# CRYPTO register map
Vendor: Texas Instruments
Peripheral module from a debugger description file (folder CC26x4).
Registers are 32-bit, write-only, reset 0x0 unless marked. A register's access mark holds for its fields unless they carry their own. Offsets are as the file gives them; lines under a group give offsets from that group; [hi:lo] are bit positions; {n}, {i} and the like mark numbered series; 'fields as' and 'values as' point back to an identical list; <NAME> marks a mode.

## CRYPTO (part 1 of 2) — DMA Crypto Core is a low power low gate count crypto core with DMA capability and local key storage.
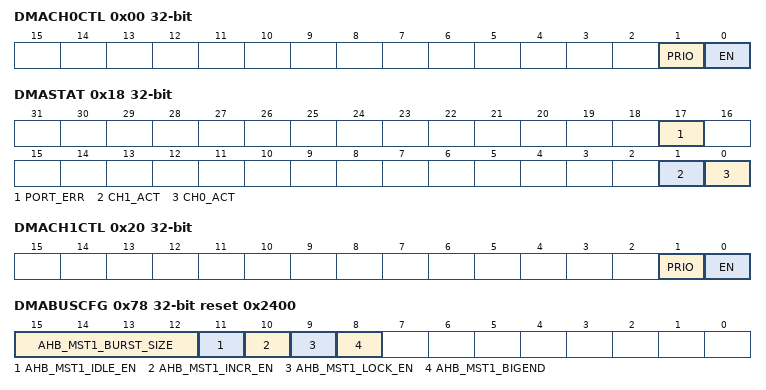
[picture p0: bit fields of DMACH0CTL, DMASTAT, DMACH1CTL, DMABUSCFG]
0x00 DMACH0CTL rw — Channel 0 Control This register is used for channel enabling and priority selection. When a channel is disabled, it becomes inactive only when all ongoing requests are finished.
  [1] PRIO — Channel priority 0: Low 1: High If both channels have the same priority, access of the channels to the external port is arbitrated using the round robin scheme. If one channel has a high priority and another one low, the channel with the high priority is served first, in case of simultaneous access requests.
  [0] EN — Channel enable 0: Disabled 1: Enable Note: Disabling an active channel interrupts the DMA operation. The ongoing block transfer completes, but no new transfers are requested.
0x04 DMACH0EXTADDR rw — Channel 0 External Address
  [31:0] ADDR — Channel external address value When read during operation, it holds the last updated external address after being sent to the master interface. Note: The crypto DMA copies out upto 3 bytes until it hits a word boundary, thus the address need not be word aligned.
0x0C DMACH0LEN rw — Channel 0 DMA Length
  [15:0] DMALEN — Channel DMA length in bytes During configuration, this register contains the DMA transfer length in bytes. During operation, it contains the last updated value of the DMA transfer length after being sent to the master interface. Note: Setting this register to a nonzero value starts the transfer if the channel is enabled. Therefore, this register must be written last when setting up a DMA channel.
0x18 DMASTAT ro — DMAC Status This register provides the actual state of each DMA channel. It also reports port errors in case these were received by the master interface module during the data transfer.
  [17] PORT_ERR — Reflects possible transfer errors on the AHB port.
  [1] CH1_ACT — A value of 1 indicates that channel 1 is active (DMA transfer on-going).
  [0] CH0_ACT — A value of 1 indicates that channel 0 is active (DMA transfer on-going).
0x1C DMASWRESET — DMAC Software Reset Software reset is used to reset the DMAC to stop all transfers and clears the port error status register. After the software reset is performed, all the channels are disabled and no new requests are performed by the channels. The DMAC waits for the existing (active) requests to finish and accordingly sets the DMASTAT.
  [0] SWRES — Software reset enable 0 : Disabled 1 : Enabled (self-cleared to 0) Completion of the software reset must be checked through the DMASTAT
0x20 DMACH1CTL rw — Channel 1 Control This register is used for channel enabling and priority selection. When a channel is disabled, it becomes inactive only when all ongoing requests are finished.
  fields as DMACH0CTL
0x24 DMACH1EXTADDR rw — Channel 1 External Address
  [31:0] ADDR — Channel external address value. When read during operation, it holds the last updated external address after being sent to the master interface. Note: The crypto DMA copies out upto 3 bytes until it hits a word boundary, thus the address need not be word aligned.
0x2C DMACH1LEN rw — Channel 1 DMA Length
  [15:0] DMALEN — Channel DMA length in bytes. During configuration, this register contains the DMA transfer length in bytes. During operation, it contains the last updated value of the DMA transfer length after being sent to the master interface. Note: Setting this register to a nonzero value starts the transfer if the channel is enabled. Therefore, this register must be written last when setting up a DMA channel.
0x78 DMABUSCFG rw reset 0x2400 — DMAC Master Run-time Parameters This register defines all the run-time parameters for the AHB master interface port. These parameters are required for the proper functioning of the EIP-101m AHB master adapter.
  [15:12] AHB_MST1_BURST_SIZE — Maximum burst size that can be performed on the AHB bus
    6=64_BYTE (64 bytes); 5=32_BYTE (32 bytes); 4=16_BYTE (16 bytes); 3=8_BYTE (8 bytes); 2=4_BYTE (4 bytes)
  [11] AHB_MST1_IDLE_EN — Idle insertion between consecutive burst transfers on AHB
    1=IDLE (Idle transfer insertion enabled); 0=NO_IDLE (Do not insert idle transfers.)
  [10] AHB_MST1_INCR_EN — Burst length type of AHB transfer
    1=SPECIFIED (Fixed length bursts or single transfers); 0=UNSPECIFIED (Unspecified length burst transfers)
  [9] AHB_MST1_LOCK_EN — Locked transform on AHB
    1=LOCKED (Transfers are locked); 0=NOT_LOCKED (Transfers are not locked)
  [8] AHB_MST1_BIGEND — Endianess for the AHB master
    1=BIG_ENDIAN; 0=LITTLE_ENDIAN
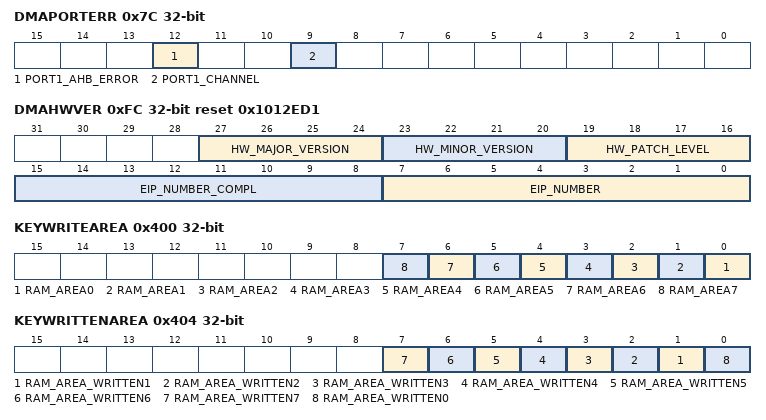
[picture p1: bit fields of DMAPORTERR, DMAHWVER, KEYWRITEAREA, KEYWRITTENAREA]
0x7C DMAPORTERR ro — DMAC Port Error Raw Status This register provides the actual status of individual port errors. It also indicates which channel is serviced by an external AHB port (which is frozen by a port error). A port error aborts operations on all serviced channels (channel enable bit is forced to 0) and prevents further transfers via that port until the error is cleared by writing to the DMASWRESET register.
  [12] PORT1_AHB_ERROR — A value of 1 indicates that the EIP-101 has detected an AHB bus error
  [9] PORT1_CHANNEL — Indicates which channel has serviced last (channel 0 or channel 1) by AHB master port.
0xFC DMAHWVER ro reset 0x1012ED1 — DMAC Version This register contains an indication (or signature) of the EIP type of this DMAC, as well as the hardware version/patch numbers.
  [27:24] HW_MAJOR_VERSION — Major version number
  [23:20] HW_MINOR_VERSION — Minor version number
  [19:16] HW_PATCH_LEVEL — Patch level Starts at 0 at first delivery of this version
  [15:8] EIP_NUMBER_COMPL — Bit-by-bit complement of the EIP_NUMBER field bits.
  [7:0] EIP_NUMBER — Binary encoding of the EIP-number of this DMA controller (209)
0x400 KEYWRITEAREA rw — Key Store Write Area This register defines where the keys should be written in the key store RAM. After writing this register, the key store module is ready to receive the keys through a DMA operation. In case the key data transfer triggered an error in the key store, the error will be available in the interrupt status register after the DMA is finished. The key store write-error is asserted when the programmed/selected area is not completely written. This error is also asserted when the DMA operation writes to ram areas that are not selected. The key store RAM is divided into 8 areas of 128 bits. 192-bit keys written in the key store RAM should start on boundaries of 256 bits. This means that writing a 192-bit key to the key store RAM must be done by writing 256 bits of data with the 64 most-significant bits set to 0. These bits are ignored by the AES engine.
  [all] fields
    1=SEL (This RAM area is selected to be written); 0=NOT_SEL (This RAM area is not selected to be written)
  [n] RAM_AREA{n} (n=0..7) — Each RAM_AREAx represents an area of 128 bits. Select the key store RAM area(s) where the key(s) needs to be written 0: RAM_AREA{n} is not selected to be written. 1: RAM_AREA{n} is selected to be written. Writing to multiple RAM locations is possible only when the selected RAM areas are sequential. Keys that require more than one RAM locations (key size is 192 or 256 bits), must start at one of the following areas: RAM_AREA0, RAM_AREA2, RAM_AREA4, or RAM_AREA6.
0x404 KEYWRITTENAREA rw — Key Store Written Area This register shows which areas of the key store RAM contain valid written keys. When a new key needs to be written to the key store, on a location that is already occupied by a valid key, this key area must be cleared first. This can be done by writing this register before the new key is written to the key store memory. Attempting to write to a key area that already contains a valid key is not allowed and results in an error.
  [n] RAM_AREA_WRITTEN{n} (n=1..7) — On read this bit returns the key area written status. This bit can be reset by writing a 1. Note: This register will be reset on a soft reset initiated by writing to DMASWRESET.SWRES. After a soft reset, all keys must be rewritten to the key store memory.
    1=WRITTEN (This RAM area is written with valid key information); 0=NOT_WRITTEN (This RAM area is not written with valid key information)
  [0] RAM_AREA_WRITTEN0 — On read this bit returns the key area written status. This bit can be reset by writing a 1. Note: This register will be reset on a soft reset initiated by writing to DMASWRESET.SWRES. After a soft reset, all keys must be rewritten to the key store memory.
0x408 KEYSIZE rw reset 0x1 — Key Store Size This register defines the size of the keys that are written with DMA. This register should be configured before writing to the KEY_STORE_WRITE_AREA register.
  [1:0] SIZE — Key size: 00: Reserved When writing this to this register, the KEY_STORE_WRITTEN_AREA register is reset.
    3=256_BIT (256 bits); 2=192_BIT (192 bits); 1=128_BIT (128 bits)
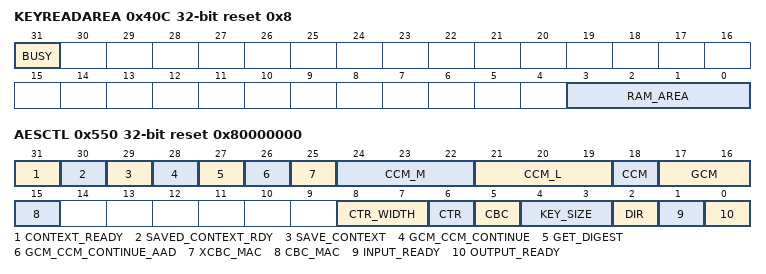
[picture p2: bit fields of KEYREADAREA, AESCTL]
0x40C KEYREADAREA access per field reset 0x8 — Key Store Read Area This register selects the key store RAM area from where the key needs to be read that will be used for an AES operation. The operation directly starts after writing this register. When the operation is finished, the status of the key store read operation is available in the interrupt status register. Key store read error is asserted when a RAM area is selected which does not contain valid written key.
  [31] BUSY ro — Key store operation busy status flag (read only): 0: Operation is complete. 1: Operation is not completed and the key store is busy.
  [3:0] RAM_AREA rw — Selects the area of the key store RAM from where the key needs to be read that will be writen to the AES engine RAM_AREA: RAM areas RAM_AREA0, RAM_AREA2, RAM_AREA4 and RAM_AREA6 are the only valid read areas for 192 and 256 bits key sizes. Only RAM areas that contain valid written keys can be selected.
    8=NO_RAM; {v}=RAM_AREA{v} (v=0..7)
0x500 AESKEY2 — AES_KEY2_0 / AES_GHASH_H_IN_0 Second Key / GHASH Key (internal, but clearable) The following registers are not accessible through the host for reading and writing. They are used to store internally calculated key information and intermediate results. However, when the host performs a write to the any of the respective AES_KEY2_n or AES_KEY3_n addresses, respectively the whole 128-bit AES_KEY2_n or AES_KEY3_n register is cleared to 0s. The AES_GHASH_H_IN_n registers (required for GHASH, which is part of GCM) are mapped to the AES_KEY2_n registers. The (intermediate) authentication result for GCM and CCM is stored in the AES_KEY3_n register.
  [31:0] AES_KEY2 — AES_KEY2/AES_GHASH_H[31:0] For GCM: -[127:0] - GHASH_H - The internally calculated GHASH key is stored in these registers. Only used for modes that use the GHASH function (GCM). -[255:128] - This register is used to store intermediate values and is initialized with 0s when loading a new key. For CCM: -[255:0] - This register is used to store intermediate values. For CBC-MAC: -[255:0] - ZEROES - This register must remain 0.
0x510 AESKEY3 — AES_KEY3_0 / AES_KEY2_4 Third Key / Second Key (internal, but clearable) The following registers are not accessible through the host for reading and writing. They are used to store internally calculated key information and intermediate results. However, when the host performs a write to the any of the respective AES_KEY2_n or AES_KEY3_n addresses, respectively the whole 128-bit AES_KEY2_n or AES_KEY3_n register is cleared to 0s. The AES_GHASH_H_IN_n registers (required for GHASH, which is part of GCM) are mapped to the AES_KEY2_n registers. The (intermediate) authentication result for GCM and CCM is stored in the AES_KEY3_n register.
  [31:0] AES_KEY3 — AES_KEY3[31:0]/AES_KEY2[159:128] For GCM: -[127:0] - GHASH_H - The internally calculated GHASH key is stored in these registers. Only used for modes that use the GHASH function (GCM). -[255:128] - This register is used to store intermediate values and is initialized with 0s when loading a new key. For CCM: -[255:0] - This register is used to store intermediate values. For CBC-MAC: -[255:0] - ZEROES - This register must remain 0.
0x540 AESIV rw — AES initialization vector registers These registers are used to provide and read the IV from the AES engine.
  [31:0] AES_IV — AES_IV[31:0] Initialization vector Used for regular non-ECB modes (CBC/CTR): -[127:0] - AES_IV - For regular AES operations (CBC and CTR) these registers must be written with a new 128-bit IV. After an operation, these registers contain the latest 128-bit result IV, generated by the EIP-120t. If CTR mode is selected, this value is incremented with 0x1: After first use - When a new data block is submitted to the engine For GCM: -[127:0] - AES_IV - For GCM operations, these registers must be written with a new 128-bit IV. After an operation, these registers contain the updated 128-bit result IV, generated by the EIP-120t. Note that bits [127:96] of the IV represent the initial counter value (which is 1 for GCM) and must therefore be initialized to 0x01000000. This value is incremented with 0x1: After first use - When a new data block is submitted to the engine. For CCM: -[127:0] - A0: For CCM this field must be written with value A0, this value is the concatenation of: A0-flags (5-bits of 0 and 3-bits 'L'), Nonce and counter value. 'L' must be a copy from the 'L' value of the AES_CTRL register. This 'L' indicates the width of the Nonce and counter. The loaded counter must be initialized to 0. The total width of A0 is 128-bit. For CBC-MAC: -[127:0] - Zeroes - For CBC-MAC this register must be written with 0s at the start of each operation. After an operation, these registers contain the 128-bit TAG output, generated by the EIP-120t.
0x550 AESCTL access per field reset 0x80000000 — AES Control AES input/output buffer control and mode register This register specifies the AES mode of operation for the EIP-120t. Electronic codebook (ECB) mode is automatically selected if bits [28:5] of this register are all 0.
  [31] CONTEXT_READY ro — If 1, this read-only status bit indicates that the context data registers can be overwritten and the host is permitted to write the next context.
  [30] SAVED_CONTEXT_RDY rw — If 1, this status bit indicates that an AES authentication TAG and/or IV block(s) is/are available for the host to retrieve. This bit is only asserted if the save_context bit is set to 1. The bit is mutual exclusive with the context_ready bit. Writing one clears the bit to 0, indicating the AES core can start its next operation. This bit is also cleared when the 4th word of the output TAG and/or IV is read. Note: All other mode bit writes are ignored when this mode bit is written with 1. Note: This bit is controlled automatically by the EIP-120t for TAG read DMA operations.
  [29] SAVE_CONTEXT rw — This bit indicates that an authentication TAG or result IV needs to be stored as a result context. Typically this bit must be set for authentication modes returning a TAG (CBC-MAC, GCM and CCM), or for basic encryption modes that require future continuation with the current result IV. If this bit is set, the engine retains its full context until the TAG and/or IV registers are read. The TAG or IV must be read before the AES engine can start a new operation.
  [28] GCM_CCM_CONTINUE rw — Continue processing of an interrupted AES-GCM or AES-CCM operation in the crypto/payload phase. Set this write-only signal to ‘1b’ together with the regular mode bit settings for a GCM or CCM operation, to continue processing from the next full block (128 bits) boundary. Before setting this bit all applicable context to resume processing must have been loaded into the engine: Keys, IV, intermediate digest/TAG and block counter. The mode can be written together with this bit, as it is part of the same register.
  [27] GET_DIGEST rw — Interrupt processing and generate an intermediate digest during an AES-GCM or AES-CCM operation. Set this write-only signal to ‘1b’ to interrupt GCM or CCM processing at the next full block (128 bits) boundary. An intermediate digest may be requested during the encryption/decryption data phase or in the AAD phase. Interruption can only be done on full block (128 bits) boundaries.
  [26] GCM_CCM_CONTINUE_AAD rw — Continue processing of an interrupted AES-GCM or AES-CCM operation in the AAD phase. Set this write-only signal to ‘1b’ together with the regular mode bit settings for a GCM or CCM operation, to continue processing from the next full AAD block (128 bits) boundary. Before setting this bit all applicable context to resume processing must have been loaded into the engine: Keys, IV, intermediate digest/TAG, block counter and the CCM align data word (the latter is for CCM mode only). The mode can be written together with this bit, as it is part of the same register.
  [25] XCBC_MAC rw — Set to ‘1’ to select AES-XCBC MAC mode. The direction bit must be set to ‘1’ for this mode. Selecting this mode requires writing the length register
  [24:22] CCM_M rw — Defines M, which indicates the length of the authentication field for CCM operations; the authentication field length equals two times (the value of CCM-M plus one). Note: The EIP-120t always returns a 128-bit authentication field, of which the M least significant bytes are valid. All values are supported.
  [21:19] CCM_L rw — Defines L, which indicates the width of the length field for CCM operations; the length field in bytes equals the value of CMM-L plus one. All values are supported.
  [18] CCM rw — If set to 1, AES-CCM is selected AES-CCM is a combined mode, using AES for authentication and encryption. Note: Selecting AES-CCM mode requires writing of the AAD length register after all other registers. Note: The CTR mode bit in this register must also be set to 1 to enable AES-CTR; selecting other AES modes than CTR mode is invalid.
  [17:16] GCM rw — Set these bits to 11 to select AES-GCM mode. AES-GCM is a combined mode, using the Galois field multiplier GF(2 to the power of 128) for authentication and AES-CTR mode for encryption. Note: The CTR mode bit in this register must also be set to 1 to enable AES-CTR Bit combination description: 00 = No GCM mode 01 = Reserved, do not select 10 = Reserved, do not select 11 = Autonomous GHASH (both H- and Y0-encrypted calculated internally) Note: The EIP-120t-1 configuration only supports mode 11 (autonomous GHASH), other GCM modes are not allowed.
  [15] CBC_MAC rw — Set to 1 to select AES-CBC MAC mode. The direction bit must be set to 1 for this mode. Selecting this mode requires writing the length register after all other registers.
  [8:7] CTR_WIDTH rw — Specifies the counter width for AES-CTR mode 00 = 32-bit counter 01 = 64-bit counter 10 = 96-bit counter 11 = 128-bit counter
    3=128_BIT (128 bits); 2=96_BIT (96 bits); 1=64_BIT (64 bits); 0=32_BIT (32 bits)
  [6] CTR rw — If set to 1, AES counter mode (CTR) is selected. Note: This bit must also be set for GCM and CCM, when encryption/decryption is required.
  [5] CBC rw — If set to 1, cipher-block-chaining (CBC) mode is selected.
  [4:3] KEY_SIZE ro — This read-only field specifies the key size. The key size is automatically configured when a new key is loaded through the key store module. 00 = N/A - Reserved 01 = 128-bit 10 = 192-bit 11 = 256-bit
  [2] DIR rw — If set to 1 an encrypt operation is performed. If set to 0 a decrypt operation is performed. This bit must be written with a 1 when CBC-MAC is selected.
  [1] INPUT_READY rw — If 1, this status bit indicates that the 16-byte AES input buffer is empty. The host is permitted to write the next block of data. Writing 0 clears the bit to 0 and indicates that the AES core can use the provided input data block. Writing 1 to this bit is ignored. Note: For DMA operations, this bit is automatically controlled by the EIP-120t. After reset, this bit is 0. After writing a context, this bit becomes 1.
  [0] OUTPUT_READY rw — If 1, this status bit indicates that an AES output block is available to be retrieved by the host. Writing 0 clears the bit to 0 and indicates that output data is read by the host. The AES core can provide a next output data block. Writing 1 to this bit is ignored. Note: For DMA operations, this bit is automatically controlled by the EIP-120t.
0x554 AESDATALEN0 — AES Crypto Length 0 (LSW) These registers are used to write the Length values to the EIP-120t. While processing, the length values decrement to 0. If both lengths are 0, the data stream is finished and a new context is requested. For basic AES modes (ECB, CBC, and CTR), a crypto length of 0 can be written if multiple streams need to be processed with the same key. Writing 0 length results in continued data requests until a new context is written. For the other modes (CBC-MAC, GCM, and CCM) no (new) data requests are done if the length decrements to or equals 0. It is advised to write a new length per packet. If the length registers decrement to 0, no new data is processed until a new context or length value is written. When writing a new mode without writing the length registers, the length register values from the previous context is reused.
  [31:0] C_LENGTH — C_LENGTH[31:0] Bits [60:0] of the crypto length registers (LSW and MSW) store the cryptographic data length in bytes for all modes. Once processing with this context is started, this length decrements to 0. Data lengths up to (261: 1) bytes are allowed. For GCM, any value up to 236 - 32 bytes can be used. This is because a 32-bit counter mode is used; the maximum number of 128-bit blocks is 232 - 2, resulting in a maximum number of bytes of 236 - 32. A write to this register triggers the engine to start using this context. This is valid for all modes except GCM and CCM. Note: For the combined modes (GCM and CCM), this length does not include the authentication only data; the authentication length is specified in the AESAUTHLEN register All modes must have a length greater than 0. For the combined modes, it is allowed to have one of the lengths equal to 0. For the basic encryption modes (ECB, CBC, and CTR) it is allowed to program zero to the length field; in that case the length is assumed infinite. All data must be byte (8-bit) aligned for stream cipher modes; bit aligned data streams are not supported by the EIP-120t. For block cipher modes, the data length must be programmed in multiples of the block cipher size, 16 bytes. For a host read operation, these registers return all-0s.
0x558 AESDATALEN1 — AES Crypto Length 1 (MSW) These registers are used to write the Length values to the EIP-120t. While processing, the length values decrement to 0. If both lengths are 0, the data stream is finished and a new context is requested. For basic AES modes (ECB, CBC, and CTR), a crypto length of 0 can be written if multiple streams need to be processed with the same key. Writing 0 length results in continued data requests until a new context is written. For the other modes (CBC-MAC, GCM and CCM) no (new) data requests are done if the length decrements to or equals 0. It is advised to write a new length per packet. If the length registers decrement to 0, no new data is processed until a new context or length value is written. When writing a new mode without writing the length registers, the length register values from the previous context is reused.
  [28:0] C_LENGTH — C_LENGTH[60:32] Bits [60:0] of the crypto length registers (LSW and MSW) store the cryptographic data length in bytes for all modes. Once processing with this context is started, this length decrements to 0. Data lengths up to (261: 1) bytes are allowed. For GCM, any value up to 236 - 32 bytes can be used. This is because a 32-bit counter mode is used; the maximum number of 128-bit blocks is 232 - 2, resulting in a maximum number of bytes of 236 - 32. A write to this register triggers the engine to start using this context. This is valid for all modes except GCM and CCM. Note: For the combined modes (GCM and CCM), this length does not include the authentication only data; the authentication length is specified in the AESAUTHLEN register All modes must have a length greater than 0. For the combined modes, it is allowed to have one of the lengths equal to 0. For the basic encryption modes (ECB, CBC, and CTR) it is allowed to program zero to the length field; in that case the length is assumed infinite. All data must be byte (8-bit) aligned for stream cipher modes; bit aligned data streams are not supported by the EIP-120t. For block cipher modes, the data length must be programmed in multiples of the block cipher size, 16 bytes. For a host read operation, these registers return all-0s.
0x55C AESAUTHLEN — AES Authentication Length
  [31:0] AUTH_LENGTH — Bits [31:0] of the authentication length register store the authentication data length in bytes for combined modes only (GCM or CCM). Supported AAD-lengths for CCM are from 0 to (2^16 - 2^8) bytes. For GCM any value up to (2^32 - 1) bytes can be used. Once processing with this context is started, this length decrements to 0. A write to this register triggers the engine to start using this context for GCM and CCM. For a host read operation, these registers return all-0s.
{0x560+4i} AESDATAOUT{i} ro (i=0..3) — Data Input/Output
  [31:0] DATA — Data register 0 for output block data from the Crypto peripheral. These bits = AES Output Data[31:0] of {127:0] For normal operations, this register is not used, since data input and output is transferred from and to the AES engine via DMA. For a Host read operation, these registers contain the 128-bit output block from the latest AES operation. Reading from a word-aligned offset within this address range will read one word (4 bytes) of data out the 4-word deep (16 bytes = 128-bits AES block) data output buffer. The words (4 words, one full block) should be read before the core will move the next block to the data output buffer. To empty the data output buffer, AESCTL.OUTPUT_READY must be written. For the modes with authentication (CBC-MAC, GCM and CCM), the invalid (message) bytes/words can be written with any data. Note: The AAD / authentication only data is not copied to the output buffer but only used for authentication.
0x560 AESDATAIN0 — AES Data Input_Output 0 The data registers are typically accessed through the DMA and not with host writes and/or reads. However, for debugging purposes the data input/output registers can be accessed via host write and read operations. The registers are used to buffer the input/output data blocks to/from the EIP-120t. Note: The data input buffer (AES_DATA_IN_n) and data output buffer (AES_DATA_OUT_n) are mapped to the same address locations. Writes (both DMA and host) to these addresses load the Input Buffer while reads pull from the Output Buffer. Therefore, for write access, the data input buffer is written; for read access, the data output buffer is read. The data input buffer must be written before starting an operation. The data output buffer contains valid data on completion of an operation. Therefore, any 128-bit data block can be split over multiple 32-bit word transfers; these can be mixed with other host transfers over the external interface.
  [31:0] AES_DATA_IN_OUT — AES input data[31:0] / AES output data[31:0] Data registers for input/output block data to/from the EIP-120t. For normal operations, this register is not used, since data input and output is transferred from and to the AES core via DMA. For a host write operation, these registers must be written with the 128-bit input block for the next AES operation. Writing at a word-aligned offset within this address range stores the word (4 bytes) of data into the corresponding position of 4-word deep (16 bytes = 128-bit AES block) data input buffer. This buffer is used for the next AES operation. If the last data block is not completely filled with valid data (see notes below), it is allowed to write only the words with valid data. Next AES operation is triggered by writing to the input_ready flag of the AES_CTRL register. For a host read operation, these registers contain the 128-bit output block from the latest AES operation. Reading from a word-aligned offset within this address range reads one word (4 bytes) of data out the 4-word deep (16 bytes = 128-bits AES block) data output buffer. The words (4 words, one full block) should be read before the core will move the next block to the data output buffer. To empty the data output buffer, the output_ready flag of the AES_CTRL register must be written. For the modes with authentication (CBC-MAC, GCM and CCM), the invalid (message) bytes/words can be written with any data. Note: AES typically operates on 128 bits block multiple input data. The CTR, GCM and CCM modes form an exception. The last block of a CTR-mode message may contain less than 128 bits (refer to [NIST 800-38A]). For GCM/CCM, the last block of both AAD and message data may contain less than 128 bits (refer to [NIST 800-38D]). The EIP-120t automatically pads or masks misaligned ending data blocks with 0s for GCM, CCM and CBC-MAC. For CTR mode, the remaining data in an unaligned data block is ignored. Note: The AAD / authentication only data is not copied to the output buffer but only used for authentication.
0x564 AESDATAIN1 — AES Data Input_Output 0 The data registers are typically accessed through the DMA and not with host writes and/or reads. However, for debugging purposes the data input/output registers can be accessed via host write and read operations. The registers are used to buffer the input/output data blocks to/from the EIP-120t. Note: The data input buffer (AES_DATA_IN_n) and data output buffer (AES_DATA_OUT_n) are mapped to the same address locations. Writes (both DMA and host) to these addresses load the Input Buffer while reads pull from the Output Buffer. Therefore, for write access, the data input buffer is written; for read access, the data output buffer is read. The data input buffer must be written before starting an operation. The data output buffer contains valid data on completion of an operation. Therefore, any 128-bit data block can be split over multiple 32-bit word transfers; these can be mixed with other host transfers over the external interface.
  [31:0] AES_DATA_IN_OUT — AES input data[31:0] / AES output data[63:32] Data registers for input/output block data to/from the EIP-120t. For normal operations, this register is not used, since data input and output is transferred from and to the AES core via DMA. For a host write operation, these registers must be written with the 128-bit input block for the next AES operation. Writing at a word-aligned offset within this address range stores the word (4 bytes) of data into the corresponding position of 4-word deep (16 bytes = 128-bit AES block) data input buffer. This buffer is used for the next AES operation. If the last data block is not completely filled with valid data (see notes below), it is allowed to write only the words with valid data. Next AES operation is triggered by writing to the input_ready flag of the AES_CTRL register. For a host read operation, these registers contain the 128-bit output block from the latest AES operation. Reading from a word-aligned offset within this address range reads one word (4 bytes) of data out the 4-word deep (16 bytes = 128-bits AES block) data output buffer. The words (4 words, one full block) should be read before the core will move the next block to the data output buffer. To empty the data output buffer, the output_ready flag of the AES_CTRL register must be written. For the modes with authentication (CBC-MAC, GCM and CCM), the invalid (message) bytes/words can be written with any data. Note: AES typically operates on 128 bits block multiple input data. The CTR, GCM and CCM modes form an exception. The last block of a CTR-mode message may contain less than 128 bits (refer to [NIST 800-38A]). For GCM/CCM, the last block of both AAD and message data may contain less than 128 bits (refer to [NIST 800-38D]). The EIP-120t automatically pads or masks misaligned ending data blocks with 0s for GCM, CCM and CBC-MAC. For CTR mode, the remaining data in an unaligned data block is ignored. Note: The AAD / authentication only data is not copied to the output buffer but only used for authentication.
0x568 AESDATAIN2 — AES Data Input_Output 2 The data registers are typically accessed via DMA and not with host writes and/or reads. However, for debugging purposes the Data Input/Output Registers can be accessed via host write and read operations. The registers are used to buffer the input/output data blocks to/from the EIP-120t. Note: The data input buffer (AES_DATA_IN_n) and data output buffer (AES_DATA_OUT_n) are mapped to the same address locations. Writes (both DMA and host) to these addresses load the Input Buffer while reads pull from the Output Buffer. Therefore, for write access, the data input buffer is written; for read access, the data output buffer is read. The data input buffer must be written before starting an operation. The data output buffer contains valid data on completion of an operation. Therefore, any 128-bit data block can be split over multiple 32-bit word transfers; these can be mixed with other host transfers over the external interface.
  [31:0] AES_DATA_IN_OUT — AES input data[95:64] / AES output data[95:64] Data registers for input/output block data to/from the EIP-120t. For normal operations, this register is not used, since data input and output is transferred from and to the AES core via DMA. For a host write operation, these registers must be written with the 128-bit input block for the next AES operation. Writing at a word-aligned offset within this address range stores the word (4 bytes) of data into the corresponding position of 4-word deep (16 bytes = 128-bit AES block) data input buffer. This buffer is used for the next AES operation. If the last data block is not completely filled with valid data (see notes below), it is allowed to write only the words with valid data. Next AES operation is triggered by writing to the input_ready flag of the AES_CTRL register. For a host read operation, these registers contain the 128-bit output block from the latest AES operation. Reading from a word-aligned offset within this address range reads one word (4 bytes) of data out the 4-word deep (16 bytes = 128-bits AES block) data output buffer. The words (4 words, one full block) should be read before the core will move the next block to the data output buffer. To empty the data output buffer, the output_ready flag of the AES_CTRL register must be written. For the modes with authentication (CBC-MAC, GCM and CCM), the invalid (message) bytes/words can be written with any data. Note: AES typically operates on 128 bits block multiple input data. The CTR, GCM and CCM modes form an exception. The last block of a CTR-mode message may contain less than 128 bits (refer to [NIST 800-38A]). For GCM/CCM, the last block of both AAD and message data may contain less than 128 bits (refer to [NIST 800-38D]). The EIP-120t automatically pads or masks misaligned ending data blocks with 0s for GCM, CCM and CBC-MAC. For CTR mode, the remaining data in an unaligned data block is ignored. Note: The AAD / authentication only data is not copied to the output buffer but only used for authentication.
0x56C AESDATAIN3 — AES Data Input_Output 3 The data registers are typically accessed via DMA and not with host writes and/or reads. However, for debugging purposes the Data Input/Output Registers can be accessed via host write and read operations. The registers are used to buffer the input/output data blocks to/from the EIP-120t. Note: The data input buffer (AES_DATA_IN_n) and data output buffer (AES_DATA_OUT_n) are mapped to the same address locations. Writes (both DMA and host) to these addresses load the Input Buffer while reads pull from the Output Buffer. Therefore, for write access, the data input buffer is written; for read access, the data output buffer is read. The data input buffer must be written before starting an operation. The data output buffer contains valid data on completion of an operation. Therefore, any 128-bit data block can be split over multiple 32-bit word transfers; these can be mixed with other host transfers over the external interface.
  [31:0] AES_DATA_IN_OUT — AES input data[127:96] / AES output data[127:96] Data registers for input/output block data to/from the EIP-120t. For normal operations, this register is not used, since data input and output is transferred from and to the AES core via DMA. For a host write operation, these registers must be written with the 128-bit input block for the next AES operation. Writing at a word-aligned offset within this address range stores the word (4 bytes) of data into the corresponding position of 4-word deep (16 bytes = 128-bit AES block) data input buffer. This buffer is used for the next AES operation. If the last data block is not completely filled with valid data (see notes below), it is allowed to write only the words with valid data. Next AES operation is triggered by writing to the input_ready flag of the AES_CTRL register. For a host read operation, these registers contain the 128-bit output block from the latest AES operation. Reading from a word-aligned offset within this address range reads one word (4 bytes) of data out the 4-word deep (16 bytes = 128-bits AES block) data output buffer. The words (4 words, one full block) should be read before the core will move the next block to the data output buffer. To empty the data output buffer, the output_ready flag of the AES_CTRL register must be written. For the modes with authentication (CBC-MAC, GCM and CCM), the invalid (message) bytes/words can be written with any data. Note: AES typically operates on 128 bits block multiple input data. The CTR, GCM and CCM modes form an exception. The last block of a CTR-mode message may contain less than 128 bits (refer to [NIST 800-38A]). For GCM/CCM, the last block of both AAD and message data may contain less than 128 bits (refer to [NIST 800-38D]). The EIP-120t automatically pads or masks misaligned ending data blocks with 0s for GCM, CCM and CBC-MAC. For CTR mode, the remaining data in an unaligned data block is ignored. Note: The AAD / authentication only data is not copied to the output buffer but only used for authentication.
0x570 AESTAGOUT ro — AES Tag Out 0 The tag registers can be accessed via DMA or directly with host reads. These registers buffer the TAG from the EIP-120t. The registers are shared with the intermediate authentication result registers, but cannot be read until the processing is finished. While processing, a read from these registers returns 0s. If an operation does not return a TAG, reading from these registers returns an IV. If an operation returns a TAG plus an IV and both need to be read by the host, the host must first read the TAG followed by the IV. Reading these in reverse order will return the IV twice.
  [31:0] AES_TAG — AES_TAG[31:0] Bits [31:0] of this register stores the authentication value for the combined and authentication only modes. For a host read operation, these registers contain the last 128-bit TAG output of the EIP-120t; the TAG is available until the next context is written. This register will only contain valid data if the TAG is available and when the AESCTL.SAVED_CONTEXT_RDY register is set. During processing or for operations/modes that do not return a TAG, reads from this register return data from the IV register.
0x5D4 AESCCMALNWRD rw — AES CCM AAD Alignment Data Word This register needs to be read and stored when an AES-CCM operation is interrupted. This value needs to be restored by writing this register, when resuming that AES-CCM operation in a later session
  [31:0] AES_CCM_ALN_WRD — This register provides access to an internal location where the AAD align data is stored for AES-CCM operation. Reading this register provides the current AAD alignment data word that is stored internally, and is used internally to concatenate to the next AAD block. Write this register to restore the AAD alignment data word for a resumed AES-CCM operation Note: This register should only be used for continued processing with AES-CCM. Do not write this register for other processing modes
0x5D8 AESBLKCNT0 rw — AES Block Counter Word 0 This counter keeps track of the number of data blocks during AES-CCM and AES-GCM operations. Reading and writing this counter allows interruption and resuming of long CCM or GCM operations. Note that internally, the block counter is used for AAD data as well as encryption/decryption data
  [31:0] AES_BLK_CNT_31_0 — [31:0] of Internal block counter for AES GCM and CCM operations. These bits read the block count value that represents the number of blocks to go. This value is valid with saved_context_ready after a request for an intermediate GCM/CCM digest. Writing these registers will restore the internal block counter to the programmed value. This only needs to be done to prepare the engine to continue processing of an interrupted GCM or CCM operation. Also refer to the get_digest and gcm_ccm_continue bits in AES_CTRL register.
